# Espressif register map
File version: 1.0
CPU: Xtensa LX6 1, little endian, no MPU, FPU, 3 interrupt priority bits
Registers are 32-bit, access not given, reset 0x0 unless marked. A register's access mark holds for its fields unless they carry their own. Offsets are from the block's base; [hi:lo] are bit positions; {n}, {i} and the like mark numbered series.

## PCNT
Base 0x3FF57000
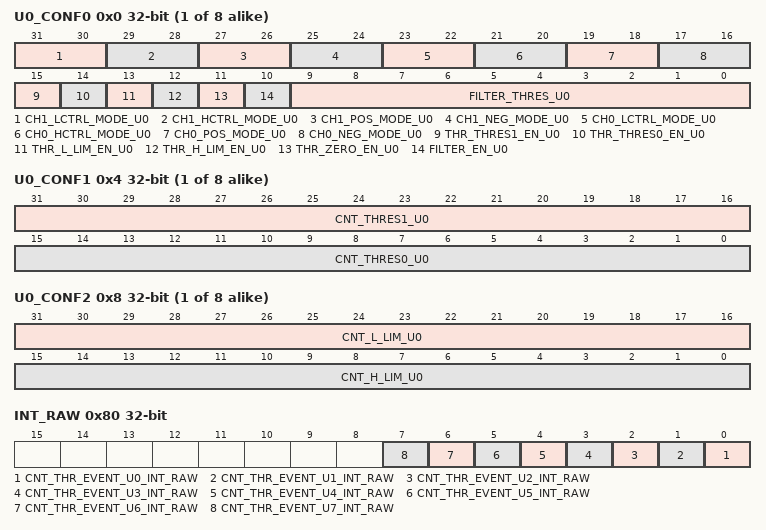
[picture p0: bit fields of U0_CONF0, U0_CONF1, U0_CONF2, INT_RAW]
{0x0+0xC*i} U{i}_CONF0 (i=0..7) — PCNT_U{i}_CONF0
  [31:30] CH1_LCTRL_MODE_U{i}, [29:28] CH1_HCTRL_MODE_U{i}, [27:26] CH1_POS_MODE_U{i}, [25:24] CH1_NEG_MODE_U{i}, [23:22] CH0_LCTRL_MODE_U{i}, [21:20] CH0_HCTRL_MODE_U{i}, [19:18] CH0_POS_MODE_U{i}, [17:16] CH0_NEG_MODE_U{i}, [15] THR_THRES1_EN_U{i}, [14] THR_THRES0_EN_U{i}, [13] THR_L_LIM_EN_U{i}, [12] THR_H_LIM_EN_U{i}, [11] THR_ZERO_EN_U{i}, [10] FILTER_EN_U{i}, [9:0] FILTER_THRES_U{i}
{0x4+0xC*i} U{i}_CONF1 (i=0..7) — PCNT_U{i}_CONF1
  [31:16] CNT_THRES1_U{i}, [15:0] CNT_THRES0_U{i}
{0x8+0xC*i} U{i}_CONF2 (i=0..7) — PCNT_U{i}_CONF2
  [31:16] CNT_L_LIM_U{i}, [15:0] CNT_H_LIM_U{i}
{0x60+4i} U{i}_CNT (i=0..7) — PCNT_U{i}_CNT
  [15:0] PLUS_CNT_U{i}
0x80 INT_RAW — PCNT_INT_RAW
  [n] CNT_THR_EVENT_U{n}_INT_RAW (n=0..7)
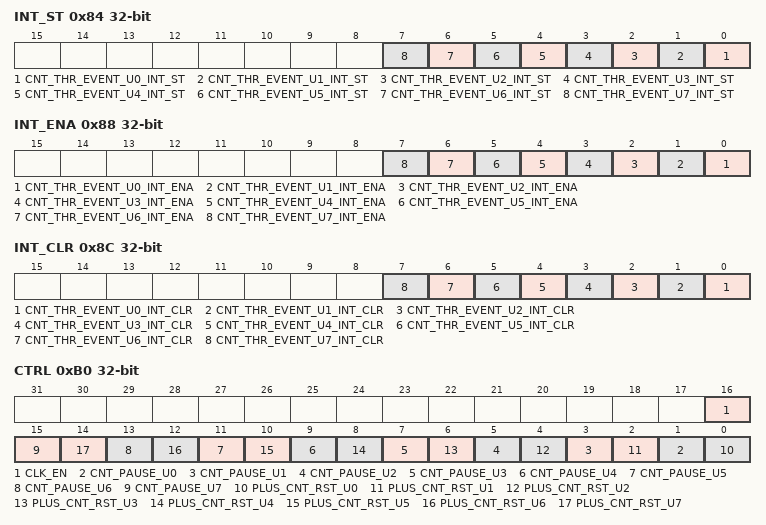
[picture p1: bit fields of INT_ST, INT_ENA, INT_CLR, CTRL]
0x84 INT_ST — PCNT_INT_ST
  [n] CNT_THR_EVENT_U{n}_INT_ST (n=0..7)
0x88 INT_ENA — PCNT_INT_ENA
  [n] CNT_THR_EVENT_U{n}_INT_ENA (n=0..7)
0x8C INT_CLR — PCNT_INT_CLR
  [n] CNT_THR_EVENT_U{n}_INT_CLR (n=0..7)
{0x90+4i} U{i}_STATUS (i=0..7) — PCNT_U{i}_STATUS
  [31:0] CORE_STATUS_U{i}
0xB0 CTRL — PCNT_CTRL
  [16] CLK_EN, [2n+1] CNT_PAUSE_U{n} (n=0..7), [2n] PLUS_CNT_RST_U{n} (n=0..7)
0xFC DATE — PCNT_DATE

## RMT
Base 0x3FF56000
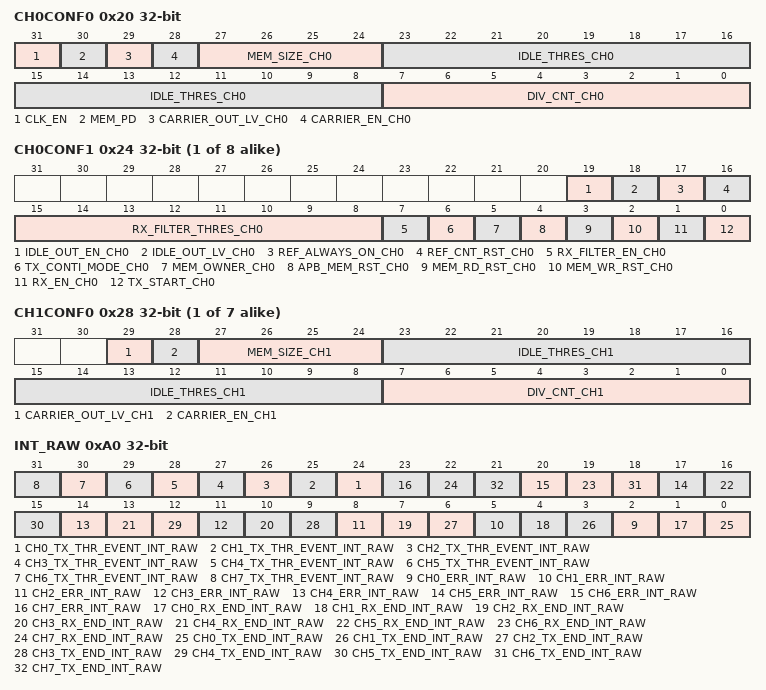
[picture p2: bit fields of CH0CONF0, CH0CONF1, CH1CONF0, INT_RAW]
0x20 CH0CONF0 — RMT_CH0CONF0
  [31] CLK_EN, [30] MEM_PD, [29] CARRIER_OUT_LV_CH0, [28] CARRIER_EN_CH0, [27:24] MEM_SIZE_CH0, [23:8] IDLE_THRES_CH0, [7:0] DIV_CNT_CH0
{0x24+8i} CH{i}CONF1 (i=0..7) — RMT_CH{i}CONF1
  [19] IDLE_OUT_EN_CH{i}, [18] IDLE_OUT_LV_CH{i}, [17] REF_ALWAYS_ON_CH{i}, [16] REF_CNT_RST_CH{i}, [15:8] RX_FILTER_THRES_CH{i}, [7] RX_FILTER_EN_CH{i}, [6] TX_CONTI_MODE_CH{i}, [5] MEM_OWNER_CH{i}, [4] APB_MEM_RST_CH{i}, [3] MEM_RD_RST_CH{i}, [2] MEM_WR_RST_CH{i}, [1] RX_EN_CH{i}, [0] TX_START_CH{i}
{0x20+8i} CH{i}CONF0 (i=1..7) — RMT_CH{i}CONF0
  [29] CARRIER_OUT_LV_CH{i}, [28] CARRIER_EN_CH{i}, [27:24] MEM_SIZE_CH{i}, [23:8] IDLE_THRES_CH{i}, [7:0] DIV_CNT_CH{i}
{0x60+4i} CH{i}STATUS (i=0..7) — RMT_CH{i}STATUS
  [31] APB_MEM_RD_ERR_CH{i}, [30] APB_MEM_WR_ERR_CH{i}, [29] MEM_EMPTY_CH{i}, [28] MEM_FULL_CH{i}, [27] MEM_OWNER_ERR_CH{i}, [26:24] STATE_CH{i}, [21:12] MEM_RADDR_EX_CH{i}, [31:0] STATUS_CH{i}, [9:0] MEM_WADDR_EX_CH{i}
{0x80+4i} CH{i}ADDR (i=0..7) — RMT_CH{i}ADDR
  [31:0] APB_MEM_ADDR_CH{i}
0xA0 INT_RAW — RMT_INT_RAW
  [n+24] CH{n}_TX_THR_EVENT_INT_RAW (n=0..7), [3n+2] CH{n}_ERR_INT_RAW (n=0..7), [3n+1] CH{n}_RX_END_INT_RAW (n=0..7), [3n] CH{n}_TX_END_INT_RAW (n=0..7)
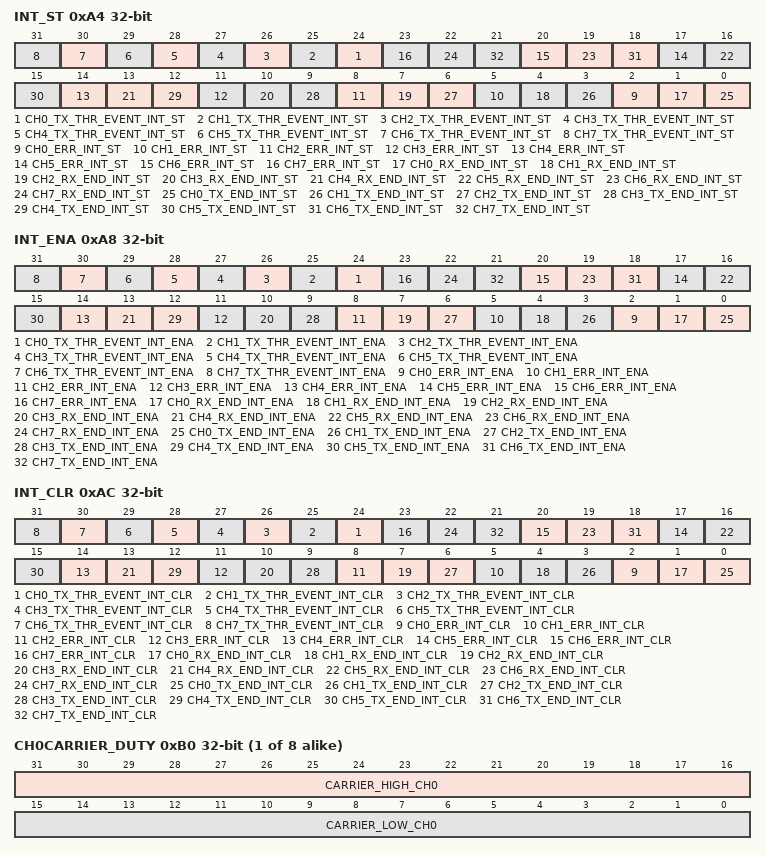
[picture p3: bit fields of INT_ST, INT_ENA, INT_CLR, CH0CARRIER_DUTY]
0xA4 INT_ST — RMT_INT_ST
  [n+24] CH{n}_TX_THR_EVENT_INT_ST (n=0..7), [3n+2] CH{n}_ERR_INT_ST (n=0..7), [3n+1] CH{n}_RX_END_INT_ST (n=0..7), [3n] CH{n}_TX_END_INT_ST (n=0..7)
0xA8 INT_ENA — RMT_INT_ENA
  [n+24] CH{n}_TX_THR_EVENT_INT_ENA (n=0..7), [3n+2] CH{n}_ERR_INT_ENA (n=0..7), [3n+1] CH{n}_RX_END_INT_ENA (n=0..7), [3n] CH{n}_TX_END_INT_ENA (n=0..7)
0xAC INT_CLR — RMT_INT_CLR
  [n+24] CH{n}_TX_THR_EVENT_INT_CLR (n=0..7), [3n+2] CH{n}_ERR_INT_CLR (n=0..7), [3n+1] CH{n}_RX_END_INT_CLR (n=0..7), [3n] CH{n}_TX_END_INT_CLR (n=0..7)
{0xB0+4i} CH{i}CARRIER_DUTY (i=0..7) — RMT_CH{i}CARRIER_DUTY
  [31:16] CARRIER_HIGH_CH{i}, [15:0] CARRIER_LOW_CH{i}
{0xD0+4i} CH{i}_TX_LIM (i=0..7) — RMT_CH{i}_TX_LIM
  [8:0] TX_LIM_CH{i}
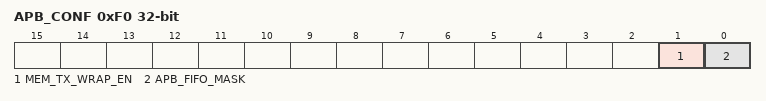
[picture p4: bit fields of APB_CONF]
0xF0 APB_CONF — RMT_APB_CONF
  [1] MEM_TX_WRAP_EN, [0] APB_FIFO_MASK
0xFC DATE — RMT_DATE

## GPIO
Base 0x3FF44000
0x00 BT_SELECT — GPIO_BT_SELECT
  [31:0] BT_SEL
0x04 OUT — GPIO_OUT
  [31:0] OUT_DATA
0x08 OUT_W1TS — GPIO_OUT_W1TS
  [31:0] OUT_DATA_W1TS
0x0C OUT_W1TC — GPIO_OUT_W1TC
  [31:0] OUT_DATA_W1TC
0x10 OUT1 — GPIO_OUT1
  [7:0] OUT1_DATA
0x14 OUT1_W1TS — GPIO_OUT1_W1TS
  [7:0] OUT1_DATA_W1TS
0x18 OUT1_W1TC — GPIO_OUT1_W1TC
  [7:0] OUT1_DATA_W1TC
0x1C SDIO_SELECT — GPIO_SDIO_SELECT
  [7:0] SDIO_SEL
0x20 ENABLE — GPIO_ENABLE
  [31:0] ENABLE_DATA
0x24 ENABLE_W1TS — GPIO_ENABLE_W1TS
  [31:0] ENABLE_DATA_W1TS
0x28 ENABLE_W1TC — GPIO_ENABLE_W1TC
  [31:0] ENABLE_DATA_W1TC
0x2C ENABLE1 — GPIO_ENABLE1
  [7:0] ENABLE1_DATA
0x30 ENABLE1_W1TS — GPIO_ENABLE1_W1TS
  [7:0] ENABLE1_DATA_W1TS
0x34 ENABLE1_W1TC — GPIO_ENABLE1_W1TC
  [7:0] ENABLE1_DATA_W1TC
0x38 STRAP — GPIO_STRAP
  [15:0] STRAPPING
0x3C IN — GPIO_IN
  [31:0] IN_DATA
0x40 IN1 — GPIO_IN1
  [7:0] IN1_DATA
0x44 STATUS — GPIO_STATUS
  [31:0] STATUS_INT
0x48 STATUS_W1TS — GPIO_STATUS_W1TS
  [31:0] STATUS_INT_W1TS
0x4C STATUS_W1TC — GPIO_STATUS_W1TC
  [31:0] STATUS_INT_W1TC
0x50 STATUS1 — GPIO_STATUS1
  [7:0] STATUS1_INT
0x54 STATUS1_W1TS — GPIO_STATUS1_W1TS
  [7:0] STATUS1_INT_W1TS
0x58 STATUS1_W1TC — GPIO_STATUS1_W1TC
  [7:0] STATUS1_INT_W1TC
0x60 ACPU_INT — GPIO_ACPU_INT
  [31:0] APPCPU_INT
0x64 ACPU_NMI_INT — GPIO_ACPU_NMI_INT
  [31:0] APPCPU_NMI_INT
0x68 PCPU_INT — GPIO_PCPU_INT
  [31:0] PROCPU_INT
0x6C PCPU_NMI_INT — GPIO_PCPU_NMI_INT
  [31:0] PROCPU_NMI_INT
0x70 CPUSDIO_INT — GPIO_CPUSDIO_INT
  [31:0] SDIO_INT
0x74 ACPU_INT1 — GPIO_ACPU_INT1
  [7:0] APPCPU_INT_H
0x78 ACPU_NMI_INT1 — GPIO_ACPU_NMI_INT1
  [7:0] APPCPU_NMI_INT_H
0x7C PCPU_INT1 — GPIO_PCPU_INT1
  [7:0] PROCPU_INT_H
0x80 PCPU_NMI_INT1 — GPIO_PCPU_NMI_INT1
  [7:0] PROCPU_NMI_INT_H
0x84 CPUSDIO_INT1 — GPIO_CPUSDIO_INT1
  [7:0] SDIO_INT_H
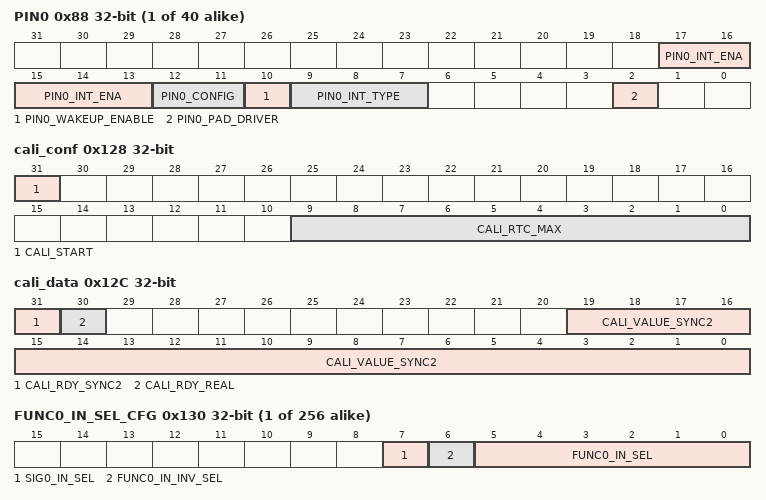
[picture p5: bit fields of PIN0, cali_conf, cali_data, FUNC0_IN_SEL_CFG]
{0x88+4i} PIN{i} (i=0..39) — GPIO_PIN{i}
  [17:13] PIN{i}_INT_ENA, [12:11] PIN{i}_CONFIG, [10] PIN{i}_WAKEUP_ENABLE, [9:7] PIN{i}_INT_TYPE, [2] PIN{i}_PAD_DRIVER
0x128 cali_conf — GPIO_cali_conf
  [31] CALI_START, [9:0] CALI_RTC_MAX
0x12C cali_data — GPIO_cali_data
  [31] CALI_RDY_SYNC2, [30] CALI_RDY_REAL, [19:0] CALI_VALUE_SYNC2
{0x130+4i} FUNC{i}_IN_SEL_CFG (i=0..255) — GPIO_FUNC{i}_IN_SEL_CFG
  [7] SIG{i}_IN_SEL, [6] FUNC{i}_IN_INV_SEL, [5:0] FUNC{i}_IN_SEL
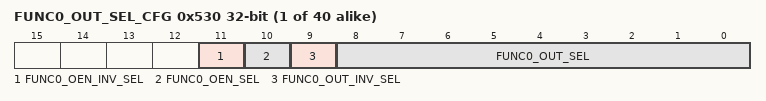
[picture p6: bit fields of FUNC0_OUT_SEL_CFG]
{0x530+4i} FUNC{i}_OUT_SEL_CFG (i=0..39) — GPIO_FUNC{i}_OUT_SEL_CFG
  [11] FUNC{i}_OEN_INV_SEL, [10] FUNC{i}_OEN_SEL, [9] FUNC{i}_OUT_INV_SEL, [8:0] FUNC{i}_OUT_SEL
